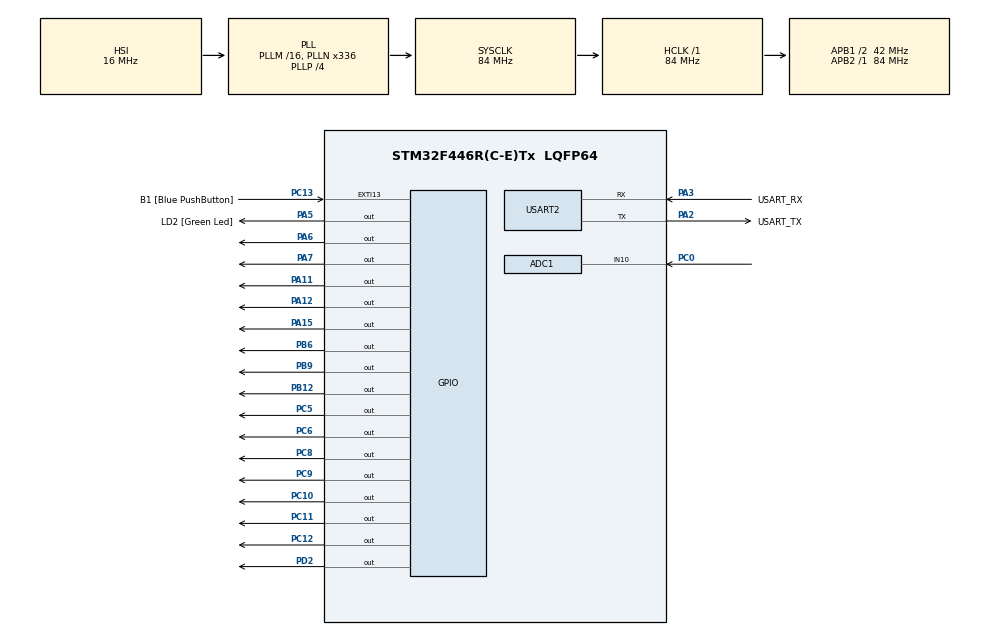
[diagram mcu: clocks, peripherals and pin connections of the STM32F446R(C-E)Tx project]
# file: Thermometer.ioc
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Mcu.Family=STM32F4
PH0-OSC_IN.Signal=RCC_OSC_IN
RCC.CortexFreq_Value=84000000
PC12.Signal=GPIO_Output
PC10.Signal=GPIO_Output
PA14.GPIO_Label=TCK
PC13.GPIO_Label=B1 [Blue PushButton]
RCC.SYSCLKSource=RCC_SYSCLKSOURCE_PLLCLK
ProjectManager.StackSize=0x400
PC8.PinState=GPIO_PIN_SET
PA12.Signal=GPIO_Output
PA7.PinState=GPIO_PIN_SET
RCC.HCLKFreq_Value=84000000
RCC.APB2TimFreq_Value=84000000
PB6.Signal=GPIO_Output
PB12.PinState=GPIO_PIN_SET
RCC.AHBFreq_Value=84000000
PH0-OSC_IN.Mode=HSE-External-Oscillator
PA12.PinState=GPIO_PIN_SET
ADC1.Channel-0\#ChannelRegularConversion=ADC_CHANNEL_10
RCC.HSE_VALUE=8000000
PC14-OSC32_IN.Mode=LSE-External-Oscillator
PA14.Mode=Serial_Wire
PC10.PinState=GPIO_PIN_SET
ADC1.SamplingTime-0\#ChannelRegularConversion=ADC_SAMPLETIME_3CYCLES
RCC.FLatency-AdvancedSettings=FLASH_LATENCY_2
PH1-OSC_OUT.Mode=HSE-External-Oscillator
Mcu.Package=LQFP64
PB9.Signal=GPIO_Output
PA6.Signal=GPIO_Output
USART2.VirtualMode=VM_ASYNC
PA2.GPIO_Label=USART_TX
PA15.Signal=GPIO_Output
RCC.APB1TimFreq_Value=84000000
PC5.Signal=GPIO_Output
PA3.Signal=USART2_RX
PB3.GPIO_Label=SWO
PC15-OSC32_OUT.Mode=LSE-External-Oscillator
ADC1.Rank-0\#ChannelRegularConversion=1
PC11.Signal=GPIO_Output
PC13.Signal=GPXTI13
PC8.Signal=GPIO_Output
PC6.Signal=GPIO_Output
PC9.PinState=GPIO_PIN_SET
PA6.PinState=GPIO_PIN_SET
PC0.Signal=ADCx_IN10
RCC.APB1CLKDivider=RCC_HCLK_DIV2
PC14-OSC32_IN.Signal=RCC_OSC32_IN
PA3.Mode=Asynchronous
PA13.Signal=SYS_JTMS-SWDIO
PC12.PinState=GPIO_PIN_SET
ProjectManager.TargetToolchain=STM32CubeIDE
RCC.USBFreq_Value=168000000
PC15-OSC32_OUT.Signal=RCC_OSC32_OUT
PC6.PinState=GPIO_PIN_SET
PA5.Signal=GPIO_Output
PD2.PinState=GPIO_PIN_SET
board=NUCLEO-F446RE
RCC.VCOOutputFreq_Value=336000000
PA15.PinState=GPIO_PIN_SET
RCC.APB2Freq_Value=84000000
PC11.PinState=GPIO_PIN_SET
PH1-OSC_OUT.Signal=RCC_OSC_OUT
PA13.Mode=Serial_Wire
Mcu.Name=STM32F446R(C-E)Tx
PA2.Signal=USART2_TX
PA13.GPIO_Label=TMS
RCC.48MHZClocksFreq_Value=84000000
PB3.Signal=SYS_JTDO-SWO
RCC.SYSCLKFreq_VALUE=84000000
ADC1.master=1
PC5.PinState=GPIO_PIN_SET
PA5.GPIO_Label=LD2 [Green Led]
PC13.GPIO_ModeDefaultEXTI=GPIO_MODE_IT_FALLING
PB6.PinState=GPIO_PIN_SET
PB9.PinState=GPIO_PIN_SET
PA11.Signal=GPIO_Output
PA14.Signal=SYS_JTCK-SWCLK
SH.ADCx_IN10.0=ADC1_IN10,IN10
ProjectManager.HeapSize=0x200
RCC.HSI_VALUE=16000000
RCC.PLLP=RCC_PLLP_DIV4
NVIC.PriorityGroup=NVIC_PRIORITYGROUP_0
ADC1.NbrOfConversionFlag=1
RCC.PLLN=336
PA2.Mode=Asynchronous
PC9.Signal=GPIO_Output
PD2.Signal=GPIO_Output
PA11.PinState=GPIO_PIN_SET
RCC.APB1Freq_Value=42000000
PB12.Signal=GPIO_Output
PA3.GPIO_Label=USART_RX
PA7.Signal=GPIO_Output

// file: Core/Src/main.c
/* USER CODE BEGIN Header */
/**
 ******************************************************************************
 * @file           : main.c
 * @brief          : Main program body
 ******************************************************************************
 * @attention
 *
 * <h2><center>&copy; Copyright (c) 2021 STMicroelectronics.
 * All rights reserved.</center></h2>
 *
 * This software component is licensed by ST under BSD 3-Clause license,
 * the "License"; You may not use this file except in compliance with the
 * License. You may obtain a copy of the License at:
 *                        opensource.org/licenses/BSD-3-Clause
 *
 ******************************************************************************
 */
/* USER CODE END Header */
#include "main.h"

ADC_HandleTypeDef hadc1;

UART_HandleTypeDef huart2;

void SystemClock_Config(void);
static void MX_GPIO_Init(void);
static void MX_USART2_UART_Init(void);
static void MX_ADC1_Init(void);

/* USER CODE BEGIN 0 */
float temperature = 0;
/* USER CODE END 0 */

int main(void)
{

  /* MCU Configuration--------------------------------------------------------*/

  /* Reset of all peripherals, Initializes the Flash interface and the Systick. */
  HAL_Init();

  /* USER CODE BEGIN Init */
  SSLL_Init();

  /* USER CODE END Init */

  /* Configure the system clock */
  SystemClock_Config();

  /* Initialize all configured peripherals */
  MX_GPIO_Init();
  MX_USART2_UART_Init();
  MX_ADC1_Init();

  /* Infinite loop */
  /* USER CODE BEGIN WHILE */
  SSLL_testDisplays();
  SSLL_testBrightness();

  SSLL_clearAllDisplays();

  SSLL_changeBrightness(1);

  while (1)
    {
      /* USER CODE END WHILE */

      /* USER CODE BEGIN 3 */

      HAL_ADC_Start(&hadc1);

      temperature = getTemperatureADCValue(&hadc1, 100);
      SSLL_displayDigit(temperature);
    }
  /* USER CODE END 3 */
}

void SystemClock_Config(void)
{
  RCC_OscInitTypeDef RCC_OscInitStruct =
    { 0 };
  RCC_ClkInitTypeDef RCC_ClkInitStruct =
    { 0 };

  /** Configure the main internal regulator output voltage
   */
  __HAL_RCC_PWR_CLK_ENABLE();
  __HAL_PWR_VOLTAGESCALING_CONFIG(PWR_REGULATOR_VOLTAGE_SCALE3);
  /** Initializes the RCC Oscillators according to the specified parameters
   * in the RCC_OscInitTypeDef structure.
   */
  RCC_OscInitStruct.OscillatorType = RCC_OSCILLATORTYPE_HSI;
  RCC_OscInitStruct.HSIState = RCC_HSI_ON;
  RCC_OscInitStruct.HSICalibrationValue = RCC_HSICALIBRATION_DEFAULT;
  RCC_OscInitStruct.PLL.PLLState = RCC_PLL_ON;
  RCC_OscInitStruct.PLL.PLLSource = RCC_PLLSOURCE_HSI;
  RCC_OscInitStruct.PLL.PLLM = 16;
  RCC_OscInitStruct.PLL.PLLN = 336;
  RCC_OscInitStruct.PLL.PLLP = RCC_PLLP_DIV4;
  RCC_OscInitStruct.PLL.PLLQ = 2;
  RCC_OscInitStruct.PLL.PLLR = 2;
  if (HAL_RCC_OscConfig(&RCC_OscInitStruct) != HAL_OK)
    {
      Error_Handler();
    }
  /** Initializes the CPU, AHB and APB buses clocks
   */
  RCC_ClkInitStruct.ClockType = RCC_CLOCKTYPE_HCLK | RCC_CLOCKTYPE_SYSCLK
      | RCC_CLOCKTYPE_PCLK1 | RCC_CLOCKTYPE_PCLK2;
  RCC_ClkInitStruct.SYSCLKSource = RCC_SYSCLKSOURCE_PLLCLK;
  RCC_ClkInitStruct.AHBCLKDivider = RCC_SYSCLK_DIV1;
  RCC_ClkInitStruct.APB1CLKDivider = RCC_HCLK_DIV2;
  RCC_ClkInitStruct.APB2CLKDivider = RCC_HCLK_DIV1;

  if (HAL_RCC_ClockConfig(&RCC_ClkInitStruct, FLASH_LATENCY_2) != HAL_OK)
    {
      Error_Handler();
    }
}

static void MX_ADC1_Init(void)
{

  ADC_ChannelConfTypeDef sConfig =
    { 0 };

  /** Configure the global features of the ADC (Clock, Resolution, Data Alignment and number of conversion)
   */
  hadc1.Instance = ADC1;
  hadc1.Init.ClockPrescaler = ADC_CLOCK_SYNC_PCLK_DIV4;
  hadc1.Init.Resolution = ADC_RESOLUTION_12B;
  hadc1.Init.ScanConvMode = DISABLE;
  hadc1.Init.ContinuousConvMode = DISABLE;
  hadc1.Init.DiscontinuousConvMode = DISABLE;
  hadc1.Init.ExternalTrigConvEdge = ADC_EXTERNALTRIGCONVEDGE_NONE;
  hadc1.Init.ExternalTrigConv = ADC_SOFTWARE_START;
  hadc1.Init.DataAlign = ADC_DATAALIGN_RIGHT;
  hadc1.Init.NbrOfConversion = 1;
  hadc1.Init.DMAContinuousRequests = DISABLE;
  hadc1.Init.EOCSelection = ADC_EOC_SEQ_CONV;
  if (HAL_ADC_Init(&hadc1) != HAL_OK)
    {
      Error_Handler();
    }
  /** Configure for the selected ADC regular channel its corresponding rank in the sequencer and its sample time.
   */
  sConfig.Channel = ADC_CHANNEL_10;
  sConfig.Rank = 1;
  sConfig.SamplingTime = ADC_SAMPLETIME_3CYCLES;
  if (HAL_ADC_ConfigChannel(&hadc1, &sConfig) != HAL_OK)
    {
      Error_Handler();
    }

}

static void MX_USART2_UART_Init(void)
{

  huart2.Instance = USART2;
  huart2.Init.BaudRate = 115200;
  huart2.Init.WordLength = UART_WORDLENGTH_8B;
  huart2.Init.StopBits = UART_STOPBITS_1;
  huart2.Init.Parity = UART_PARITY_NONE;
  huart2.Init.Mode = UART_MODE_TX_RX;
  huart2.Init.HwFlowCtl = UART_HWCONTROL_NONE;
  huart2.Init.OverSampling = UART_OVERSAMPLING_16;
  if (HAL_UART_Init(&huart2) != HAL_OK)
    {
      Error_Handler();
    }

}

static void MX_GPIO_Init(void)
{
  GPIO_InitTypeDef GPIO_InitStruct =
    { 0 };

  /* GPIO Ports Clock Enable */
  __HAL_RCC_GPIOC_CLK_ENABLE();
  __HAL_RCC_GPIOH_CLK_ENABLE();
  __HAL_RCC_GPIOA_CLK_ENABLE();
  __HAL_RCC_GPIOB_CLK_ENABLE();
  __HAL_RCC_GPIOD_CLK_ENABLE();

  /*Configure GPIO pin Output Level */
  HAL_GPIO_WritePin(LD2_GPIO_Port, LD2_Pin, GPIO_PIN_RESET);

  /*Configure GPIO pin Output Level */
  HAL_GPIO_WritePin(
      GPIOA, GPIO_PIN_6 | GPIO_PIN_7 | GPIO_PIN_11 | GPIO_PIN_12 | GPIO_PIN_15,
      GPIO_PIN_SET);

  /*Configure GPIO pin Output Level */
  HAL_GPIO_WritePin(
      GPIOC,
      GPIO_PIN_5 | GPIO_PIN_6 | GPIO_PIN_8 | GPIO_PIN_9 | GPIO_PIN_10
	  | GPIO_PIN_11 | GPIO_PIN_12,
      GPIO_PIN_SET);

  /*Configure GPIO pin Output Level */
  HAL_GPIO_WritePin(GPIOB, GPIO_PIN_12 | GPIO_PIN_6 | GPIO_PIN_9, GPIO_PIN_SET);

  /*Configure GPIO pin Output Level */
  HAL_GPIO_WritePin(GPIOD, GPIO_PIN_2, GPIO_PIN_SET);

  /*Configure GPIO pin : B1_Pin */
  GPIO_InitStruct.Pin = B1_Pin;
  GPIO_InitStruct.Mode = GPIO_MODE_IT_FALLING;
  GPIO_InitStruct.Pull = GPIO_NOPULL;
  HAL_GPIO_Init(B1_GPIO_Port, &GPIO_InitStruct);

  /*Configure GPIO pins : LD2_Pin PA6 PA7 PA11
   PA12 PA15 */
  GPIO_InitStruct.Pin = LD2_Pin | GPIO_PIN_6 | GPIO_PIN_7 | GPIO_PIN_11
      | GPIO_PIN_12 | GPIO_PIN_15;
  GPIO_InitStruct.Mode = GPIO_MODE_OUTPUT_PP;
  GPIO_InitStruct.Pull = GPIO_NOPULL;
  GPIO_InitStruct.Speed = GPIO_SPEED_FREQ_LOW;
  HAL_GPIO_Init(GPIOA, &GPIO_InitStruct);

  /*Configure GPIO pins : PC5 PC6 PC8 PC9
   PC10 PC11 PC12 */
  GPIO_InitStruct.Pin = GPIO_PIN_5 | GPIO_PIN_6 | GPIO_PIN_8 | GPIO_PIN_9
      | GPIO_PIN_10 | GPIO_PIN_11 | GPIO_PIN_12;
  GPIO_InitStruct.Mode = GPIO_MODE_OUTPUT_PP;
  GPIO_InitStruct.Pull = GPIO_NOPULL;
  GPIO_InitStruct.Speed = GPIO_SPEED_FREQ_LOW;
  HAL_GPIO_Init(GPIOC, &GPIO_InitStruct);

  /*Configure GPIO pins : PB12 PB6 PB9 */
  GPIO_InitStruct.Pin = GPIO_PIN_12 | GPIO_PIN_6 | GPIO_PIN_9;
  GPIO_InitStruct.Mode = GPIO_MODE_OUTPUT_PP;
  GPIO_InitStruct.Pull = GPIO_NOPULL;
  GPIO_InitStruct.Speed = GPIO_SPEED_FREQ_LOW;
  HAL_GPIO_Init(GPIOB, &GPIO_InitStruct);

  /*Configure GPIO pin : PD2 */
  GPIO_InitStruct.Pin = GPIO_PIN_2;
  GPIO_InitStruct.Mode = GPIO_MODE_OUTPUT_PP;
  GPIO_InitStruct.Pull = GPIO_NOPULL;
  GPIO_InitStruct.Speed = GPIO_SPEED_FREQ_LOW;
  HAL_GPIO_Init(GPIOD, &GPIO_InitStruct);

}

void Error_Handler(void)
{
  __disable_irq();
  while (1)
    {
    }
}

/************************ (C) COPYRIGHT STMicroelectronics *****END OF FILE****/
